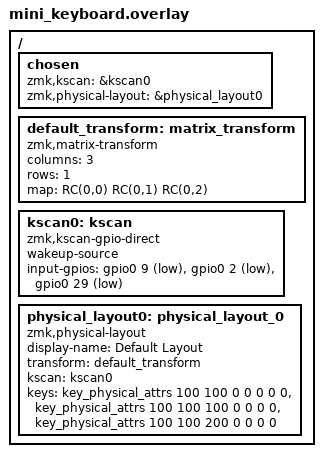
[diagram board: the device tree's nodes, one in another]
#include <dt-bindings/zmk/matrix_transform.h>
#include <physical_layouts.dtsi>

/ {
    chosen {
        zmk,kscan = &kscan0;
        zmk,physical-layout = &physical_layout0;
    };

    default_transform: matrix_transform {
        compatible = "zmk,matrix-transform";
        columns = <3>;
        rows = <1>;
        map = <
            RC(0,0) RC(0,1) RC(0,2)
        >;
    };

    kscan0: kscan {
        compatible = "zmk,kscan-gpio-direct";
        wakeup-source;

        input-gpios
            = <&gpio0 9 (GPIO_ACTIVE_LOW | GPIO_PULL_UP)>
            , <&gpio0 2 (GPIO_ACTIVE_LOW | GPIO_PULL_UP)>
            , <&gpio0 29 (GPIO_ACTIVE_LOW | GPIO_PULL_UP)>
            ;
    };

    physical_layout0: physical_layout_0 {
        compatible = "zmk,physical-layout";
        display-name = "Default Layout";
        transform = <&default_transform>;
        kscan = <&kscan0>;
        keys  // Layout for 3 keys in a row
            = <&key_physical_attrs 100 100 0 0 0 0 0>
            , <&key_physical_attrs 100 100 100 0 0 0 0>
            , <&key_physical_attrs 100 100 200 0 0 0 0>
            ;
    };
};
